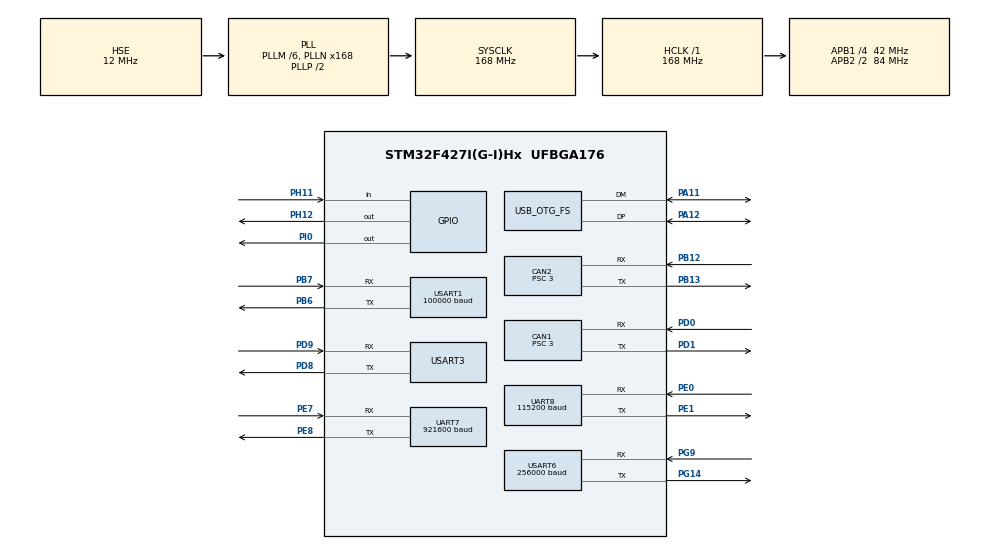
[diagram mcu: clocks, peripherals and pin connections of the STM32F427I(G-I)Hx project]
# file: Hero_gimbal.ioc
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CAN1.ABOM=ENABLE
CAN1.BS1=CAN_BS1_9TQ
CAN1.BS2=CAN_BS2_4TQ
CAN1.CalculateBaudRate=1000000
CAN1.CalculateTimeBit=1000
CAN1.CalculateTimeQuantum=71.42857142857143
CAN1.NART=ENABLE
CAN1.Prescaler=3
CAN1.TTCM=DISABLE
CAN2.ABOM=ENABLE
CAN2.BS1=CAN_BS1_9TQ
CAN2.BS2=CAN_BS2_4TQ
CAN2.CalculateBaudRate=1000000
CAN2.CalculateTimeBit=1000
CAN2.CalculateTimeQuantum=71.42857142857143
CAN2.NART=ENABLE
CAN2.Prescaler=3
Dma.Request0=USART1_RX
Dma.Request1=USART3_RX
Dma.Request2=USART3_TX
Dma.Request3=USART6_TX
Dma.Request4=UART8_RX
Dma.Request5=UART8_TX
Dma.Request6=UART7_RX
Dma.Request7=USART6_RX
Dma.UART7_RX.6.Direction=DMA_PERIPH_TO_MEMORY
Dma.UART7_RX.6.FIFOMode=DMA_FIFOMODE_DISABLE
Dma.UART7_RX.6.Instance=DMA1_Stream3
Dma.UART7_RX.6.MemDataAlignment=DMA_MDATAALIGN_BYTE
Dma.UART7_RX.6.MemInc=DMA_MINC_ENABLE
Dma.UART7_RX.6.Mode=DMA_NORMAL
Dma.UART7_RX.6.PeriphDataAlignment=DMA_PDATAALIGN_BYTE
Dma.UART7_RX.6.PeriphInc=DMA_PINC_DISABLE
Dma.UART7_RX.6.Priority=DMA_PRIORITY_LOW
Dma.UART8_RX.4.Direction=DMA_PERIPH_TO_MEMORY
Dma.UART8_RX.4.FIFOMode=DMA_FIFOMODE_DISABLE
Dma.UART8_RX.4.Instance=DMA1_Stream6
Dma.UART8_RX.4.MemDataAlignment=DMA_MDATAALIGN_BYTE
Dma.UART8_RX.4.MemInc=DMA_MINC_ENABLE
Dma.UART8_RX.4.Mode=DMA_NORMAL
Dma.UART8_RX.4.PeriphDataAlignment=DMA_PDATAALIGN_BYTE
Dma.UART8_RX.4.PeriphInc=DMA_PINC_DISABLE
Dma.UART8_RX.4.Priority=DMA_PRIORITY_LOW
Dma.UART8_TX.5.Direction=DMA_MEMORY_TO_PERIPH
Dma.UART8_TX.5.FIFOMode=DMA_FIFOMODE_DISABLE
Dma.UART8_TX.5.Instance=DMA1_Stream0
Dma.UART8_TX.5.MemDataAlignment=DMA_MDATAALIGN_BYTE
Dma.UART8_TX.5.MemInc=DMA_MINC_ENABLE
Dma.UART8_TX.5.Mode=DMA_NORMAL
Dma.UART8_TX.5.PeriphDataAlignment=DMA_PDATAALIGN_BYTE
Dma.UART8_TX.5.PeriphInc=DMA_PINC_DISABLE
Dma.UART8_TX.5.Priority=DMA_PRIORITY_LOW
Dma.USART1_RX.0.Direction=DMA_PERIPH_TO_MEMORY
Dma.USART1_RX.0.FIFOMode=DMA_FIFOMODE_DISABLE
Dma.USART1_RX.0.Instance=DMA2_Stream2
Dma.USART1_RX.0.MemDataAlignment=DMA_MDATAALIGN_BYTE
Dma.USART1_RX.0.MemInc=DMA_MINC_ENABLE
Dma.USART1_RX.0.Mode=DMA_NORMAL
Dma.USART1_RX.0.PeriphDataAlignment=DMA_PDATAALIGN_BYTE
Dma.USART1_RX.0.PeriphInc=DMA_PINC_DISABLE
Dma.USART1_RX.0.Priority=DMA_PRIORITY_LOW
Dma.USART3_RX.1.Direction=DMA_PERIPH_TO_MEMORY
Dma.USART3_RX.1.FIFOMode=DMA_FIFOMODE_DISABLE
Dma.USART3_RX.1.Instance=DMA1_Stream1
Dma.USART3_RX.1.MemDataAlignment=DMA_MDATAALIGN_BYTE
Dma.USART3_RX.1.MemInc=DMA_MINC_ENABLE
Dma.USART3_RX.1.Mode=DMA_NORMAL
Dma.USART3_RX.1.PeriphDataAlignment=DMA_PDATAALIGN_BYTE
Dma.USART3_RX.1.PeriphInc=DMA_PINC_DISABLE
Dma.USART3_RX.1.Priority=DMA_PRIORITY_LOW
Dma.USART3_TX.2.Direction=DMA_MEMORY_TO_PERIPH
Dma.USART3_TX.2.FIFOMode=DMA_FIFOMODE_DISABLE
Dma.USART3_TX.2.Instance=DMA1_Stream4
Dma.USART3_TX.2.MemDataAlignment=DMA_MDATAALIGN_BYTE
Dma.USART3_TX.2.MemInc=DMA_MINC_ENABLE
Dma.USART3_TX.2.Mode=DMA_NORMAL
Dma.USART3_TX.2.PeriphDataAlignment=DMA_PDATAALIGN_BYTE
Dma.USART3_TX.2.PeriphInc=DMA_PINC_DISABLE
Dma.USART3_TX.2.Priority=DMA_PRIORITY_LOW
Dma.USART6_TX.3.Direction=DMA_MEMORY_TO_PERIPH
Dma.USART6_TX.3.FIFOMode=DMA_FIFOMODE_DISABLE
Dma.USART6_TX.3.Instance=DMA2_Stream6
Dma.USART6_TX.3.MemDataAlignment=DMA_MDATAALIGN_BYTE
Dma.USART6_TX.3.MemInc=DMA_MINC_ENABLE
Dma.USART6_TX.3.Mode=DMA_NORMAL
Dma.USART6_TX.3.PeriphDataAlignment=DMA_PDATAALIGN_BYTE
Dma.USART6_TX.3.PeriphInc=DMA_PINC_DISABLE
Dma.USART6_TX.3.Priority=DMA_PRIORITY_LOW
Dma.USART6_RX.7.Direction=DMA_PERIPH_TO_MEMORY
Dma.USART6_RX.7.FIFOMode=DMA_FIFOMODE_DISABLE
Dma.USART6_RX.7.Instance=DMA2_Stream1
Dma.USART6_RX.7.MemDataAlignment=DMA_MDATAALIGN_BYTE
Dma.USART6_RX.7.MemInc=DMA_MINC_ENABLE
Dma.USART6_RX.7.Mode=DMA_NORMAL
Dma.USART6_RX.7.PeriphDataAlignment=DMA_PDATAALIGN_BYTE
Dma.USART6_RX.7.PeriphInc=DMA_PINC_DISABLE
Dma.USART6_RX.7.Priority=DMA_PRIORITY_LOW
FREERTOS.Tasks01=defaultTask,24,128,StartDefaultTask,Default,NULL,Dynamic,NULL,NULL
FREERTOS.configTOTAL_HEAP_SIZE=32768
Mcu.Family=STM32F4
Mcu.Name=STM32F427I(G-I)Hx
Mcu.Package=UFBGA176
NVIC.CAN1_RX0_IRQn=true\:6\:0\:true\:false\:true\:true\:true\:true\:true
NVIC.CAN1_RX1_IRQn=true\:6\:0\:true\:false\:true\:true\:true\:true\:true
NVIC.CAN2_RX0_IRQn=true\:6\:0\:true\:false\:true\:true\:true\:true\:true
NVIC.CAN2_RX1_IRQn=true\:6\:0\:true\:false\:true\:true\:true\:true\:true
NVIC.DMA1_Stream0_IRQn=true\:5\:0\:false\:false\:true\:true\:false\:true\:true
NVIC.DMA1_Stream1_IRQn=true\:5\:0\:false\:false\:true\:true\:false\:true\:true
NVIC.DMA1_Stream3_IRQn=true\:5\:0\:false\:false\:true\:true\:false\:true\:true
NVIC.DMA1_Stream4_IRQn=true\:5\:0\:false\:false\:true\:false\:false\:true\:true
NVIC.DMA1_Stream6_IRQn=true\:5\:0\:false\:false\:true\:true\:false\:true\:true
NVIC.DMA2_Stream1_IRQn=true\:5\:0\:false\:false\:true\:true\:false\:true\:true
NVIC.DMA2_Stream2_IRQn=true\:5\:0\:false\:false\:true\:true\:false\:true\:true
NVIC.DMA2_Stream6_IRQn=true\:5\:0\:false\:false\:true\:true\:false\:true\:true
NVIC.OTG_FS_IRQn=true\:5\:0\:false\:false\:true\:true\:true\:true\:true
NVIC.PriorityGroup=NVIC_PRIORITYGROUP_4
NVIC.TIM8_TRG_COM_TIM14_IRQn=true\:15\:0\:false\:false\:true\:false\:false\:true\:true
NVIC.TimeBase=TIM8_TRG_COM_TIM14_IRQn
NVIC.TimeBaseIP=TIM14
NVIC.UART7_IRQn=true\:5\:0\:false\:false\:true\:true\:true\:true\:true
NVIC.UART8_IRQn=true\:5\:0\:true\:false\:true\:true\:true\:true\:true
NVIC.USART1_IRQn=true\:6\:0\:true\:false\:true\:true\:false\:true\:true
NVIC.USART3_IRQn=true\:6\:0\:true\:false\:true\:true\:false\:true\:true
NVIC.USART6_IRQn=true\:6\:0\:true\:false\:true\:true\:false\:true\:true
PA11.Mode=Device_Only
PA11.Signal=USB_OTG_FS_DM
PA12.Mode=Device_Only
PA12.Signal=USB_OTG_FS_DP
PA13.Mode=Serial_Wire
PA13.Signal=SYS_JTMS-SWDIO
PA14.Mode=Serial_Wire
PA14.Signal=SYS_JTCK-SWCLK
PB12.Mode=CAN_Activate
PB12.Signal=CAN2_RX
PB13.Mode=CAN_Activate
PB13.Signal=CAN2_TX
PB6.Mode=Asynchronous
PB6.Signal=USART1_TX
PB7.Mode=Asynchronous
PB7.Signal=USART1_RX
PD0.Mode=CAN_Activate
PD0.Signal=CAN1_RX
PD1.Mode=CAN_Activate
PD1.Signal=CAN1_TX
PD8.Mode=Asynchronous
PD8.Signal=USART3_TX
PD9.Mode=Asynchronous
PD9.Signal=USART3_RX
PE0.Mode=Asynchronous
PE0.Signal=UART8_RX
PE1.Mode=Asynchronous
PE1.Signal=UART8_TX
PE7.Mode=Asynchronous
PE7.Signal=UART7_RX
PE8.Mode=Asynchronous
PE8.Signal=UART7_TX
PG14.Mode=Asynchronous
PG14.Signal=USART6_TX
PG9.Mode=Asynchronous
PG9.Signal=USART6_RX
PH0/OSC_IN.Mode=HSE-External-Oscillator
PH0/OSC_IN.Signal=RCC_OSC_IN
PH1/OSC_OUT.Mode=HSE-External-Oscillator
PH1/OSC_OUT.Signal=RCC_OSC_OUT
PH11.GPIO_PuPd=GPIO_PULLDOWN
PH11.Signal=GPIO_Input
PH12.Signal=GPIO_Output
PI0.Signal=GPIO_Output
ProjectManager.HeapSize=0x200
ProjectManager.StackSize=0x1000
ProjectManager.TargetToolchain=MDK-ARM V5.32
RCC.48MHZClocksFreq_Value=48000000
RCC.AHBFreq_Value=168000000
RCC.APB1CLKDivider=RCC_HCLK_DIV4
RCC.APB1Freq_Value=42000000
RCC.APB1TimFreq_Value=84000000
RCC.APB2CLKDivider=RCC_HCLK_DIV2
RCC.APB2Freq_Value=84000000
RCC.APB2TimFreq_Value=168000000
RCC.CortexFreq_Value=168000000
RCC.HCLKFreq_Value=168000000
RCC.HSE_VALUE=12000000
RCC.HSI_VALUE=16000000
RCC.LSE_VALUE=32768
RCC.PLLM=6
RCC.PLLN=168
RCC.PLLQ=7
RCC.SYSCLKFreq_VALUE=168000000
RCC.SYSCLKSource=RCC_SYSCLKSOURCE_PLLCLK
RCC.VCOOutputFreq_Value=336000000
UART7.BaudRate=921600
UART7.VirtualMode=Asynchronous
UART8.BaudRate=115200
UART8.VirtualMode=Asynchronous
USART1.BaudRate=100000
USART1.Parity=PARITY_EVEN
USART1.VirtualMode=VM_ASYNC
USART1.WordLength=WORDLENGTH_9B
USART3.VirtualMode=VM_ASYNC
USART6.BaudRate=256000
USART6.VirtualMode=VM_ASYNC
USB_DEVICE.CLASS_NAME_FS=CDC
USB_DEVICE.VirtualMode-CDC_FS=Cdc
USB_DEVICE.VirtualModeFS=Cdc_FS
USB_OTG_FS.VirtualMode=Device_Only
VP_FREERTOS_VS_CMSIS_V2.Mode=CMSIS_V2
VP_SYS_VS_tim14.Mode=TIM14
VP_TIM6_VS_ClockSourceINT.Mode=Enable_Timer
VP_USB_DEVICE_VS_USB_DEVICE_CDC_FS.Mode=CDC_FS
board=custom

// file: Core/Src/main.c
/* USER CODE BEGIN Header */
/**
  ******************************************************************************
  * @file           : main.c
  * @brief          : Main program body
  ******************************************************************************
  * @attention
  *
  * Copyright (c) 2026 STMicroelectronics.
  * All rights reserved.
  *
  * This software is licensed under terms that can be found in the LICENSE file
  * in the root directory of this software component.
  * If no LICENSE file comes with this software, it is provided AS-IS.
  *
  ******************************************************************************
  */
/* USER CODE END Header */
#include "main.h"
#include "cmsis_os.h"
#include "can.h"
#include "dma.h"
#include "tim.h"
#include "usart.h"
#include "usb_device.h"
#include "gpio.h"

/* USER CODE BEGIN Includes */
#include "app/yaw_id_app.h"
/* USER CODE END Includes */

void SystemClock_Config(void);
void MX_FREERTOS_Init(void);

int main(void)
{

  /* MCU Configuration--------------------------------------------------------*/

  /* Reset of all peripherals, Initializes the Flash interface and the Systick. */
  HAL_Init();

  /* Configure the system clock */
  SystemClock_Config();

  /* Initialize all configured peripherals */
  MX_GPIO_Init();
  MX_DMA_Init();
  MX_CAN1_Init();
  MX_CAN2_Init();
  MX_USART1_UART_Init();
  MX_USART3_UART_Init();
  MX_USART6_UART_Init();
  MX_TIM6_Init();
  MX_UART8_Init();
  MX_UART7_Init();

  /* Init scheduler */
  osKernelInitialize();  /* Call init function for freertos objects (in cmsis_os2.c) */
  MX_FREERTOS_Init();

  /* Start scheduler */
  osKernelStart();

  /* We should never get here as control is now taken by the scheduler */

  /* Infinite loop */
  while (1)
  {

  }
}

void SystemClock_Config(void)
{
  RCC_OscInitTypeDef RCC_OscInitStruct = {0};
  RCC_ClkInitTypeDef RCC_ClkInitStruct = {0};

  /** Configure the main internal regulator output voltage
  */
  __HAL_RCC_PWR_CLK_ENABLE();
  __HAL_PWR_VOLTAGESCALING_CONFIG(PWR_REGULATOR_VOLTAGE_SCALE1);

  /** Initializes the RCC Oscillators according to the specified parameters
  * in the RCC_OscInitTypeDef structure.
  */
  RCC_OscInitStruct.OscillatorType = RCC_OSCILLATORTYPE_HSE;
  RCC_OscInitStruct.HSEState = RCC_HSE_ON;
  RCC_OscInitStruct.PLL.PLLState = RCC_PLL_ON;
  RCC_OscInitStruct.PLL.PLLSource = RCC_PLLSOURCE_HSE;
  RCC_OscInitStruct.PLL.PLLM = 6;
  RCC_OscInitStruct.PLL.PLLN = 168;
  RCC_OscInitStruct.PLL.PLLP = RCC_PLLP_DIV2;
  RCC_OscInitStruct.PLL.PLLQ = 7;
  if (HAL_RCC_OscConfig(&RCC_OscInitStruct) != HAL_OK)
  {
    Error_Handler();
  }

  /** Initializes the CPU, AHB and APB buses clocks
  */
  RCC_ClkInitStruct.ClockType = RCC_CLOCKTYPE_HCLK|RCC_CLOCKTYPE_SYSCLK
                              |RCC_CLOCKTYPE_PCLK1|RCC_CLOCKTYPE_PCLK2;
  RCC_ClkInitStruct.SYSCLKSource = RCC_SYSCLKSOURCE_PLLCLK;
  RCC_ClkInitStruct.AHBCLKDivider = RCC_SYSCLK_DIV1;
  RCC_ClkInitStruct.APB1CLKDivider = RCC_HCLK_DIV4;
  RCC_ClkInitStruct.APB2CLKDivider = RCC_HCLK_DIV2;

  if (HAL_RCC_ClockConfig(&RCC_ClkInitStruct, FLASH_LATENCY_5) != HAL_OK)
  {
    Error_Handler();
  }
}

void HAL_TIM_PeriodElapsedCallback(TIM_HandleTypeDef *htim)
{
  if (htim->Instance == TIM14)
  {
    HAL_IncTick();
  }
  /* USER CODE BEGIN Callback 1 */
  if (htim->Instance == TIM6) YawId_TimerIrq();
/* USER CODE END Callback 1 */
}

void Error_Handler(void)
{
  /* USER CODE BEGIN Error_Handler_Debug */
  YawId_FaultStop();
  __disable_irq();
  while (1) {}
/* USER CODE END Error_Handler_Debug */
}

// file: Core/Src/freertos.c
/* USER CODE BEGIN Header */
/**
  ******************************************************************************
  * File Name          : freertos.c
  * Description        : Code for freertos applications
  ******************************************************************************
  * @attention
  *
  * Copyright (c) 2026 STMicroelectronics.
  * All rights reserved.
  *
  * This software is licensed under terms that can be found in the LICENSE file
  * in the root directory of this software component.
  * If no LICENSE file comes with this software, it is provided AS-IS.
  *
  ******************************************************************************
  */
/* USER CODE END Header */

#include "FreeRTOS.h"
#include "task.h"
#include "main.h"
#include "cmsis_os.h"

/* USER CODE BEGIN Includes */
#include "app/yaw_id_app.h"
/* USER CODE END Includes */

/* Definitions for defaultTask */
osThreadId_t defaultTaskHandle;
const osThreadAttr_t defaultTask_attributes = {
  .name = "defaultTask",
  .stack_size = 512 * 4,
  .priority = (osPriority_t) osPriorityNormal,
};

void StartDefaultTask(void *argument);

extern void MX_USB_DEVICE_Init(void);
void MX_FREERTOS_Init(void); /* (MISRA C 2004 rule 8.1) */

void MX_FREERTOS_Init(void) {

  /* Create the thread(s) */
  /* creation of defaultTask */
  defaultTaskHandle = osThreadNew(StartDefaultTask, NULL, &defaultTask_attributes);

  /* USER CODE BEGIN RTOS_THREADS */
  YawId_CreateTasks();
/* USER CODE END RTOS_THREADS */

}

void StartDefaultTask(void *argument)
{
  /* init code for USB_DEVICE */
  MX_USB_DEVICE_Init();
  for(;;)
  {
    osDelay(1);
  }
}
